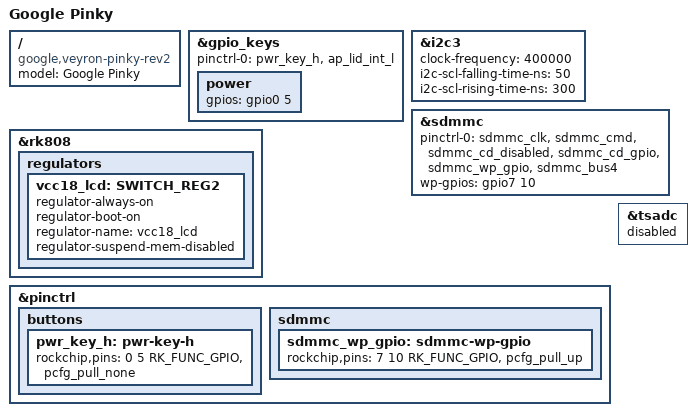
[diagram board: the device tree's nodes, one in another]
/*
 * Google Veyron Pinky Rev 2 board device tree source
 *
 * Copyright 2014 Google, Inc
 *
 * This program is free software; you can redistribute it and/or modify
 * it under the terms of the GNU General Public License version 2 as
 * published by the Free Software Foundation.
 */

/dts-v1/;
#include "rk3288-veyron-chromebook.dtsi"
#include "cros-ec-sbs.dtsi"

/ {
	model = "Google Pinky";
	compatible = "google,veyron-pinky-rev2", "google,veyron-pinky",
		     "google,veyron", "rockchip,rk3288";
};

&gpio_keys {
	pinctrl-0 = <&pwr_key_h &ap_lid_int_l>;

	power {
		gpios = <&gpio0 5 GPIO_ACTIVE_HIGH>;
	};
};

/* Touchpad connector */
&i2c3 {
	status = "okay";

	clock-frequency = <400000>;
	i2c-scl-falling-time-ns = <50>;
	i2c-scl-rising-time-ns = <300>;
};

&sdmmc {
	pinctrl-names = "default";
	pinctrl-0 = <&sdmmc_clk &sdmmc_cmd &sdmmc_cd_disabled &sdmmc_cd_gpio
		     &sdmmc_wp_gpio &sdmmc_bus4>;
	wp-gpios = <&gpio7 10 GPIO_ACTIVE_HIGH>;
};

&rk808 {
	regulators {
		vcc18_lcd: SWITCH_REG2 {
			regulator-always-on;
			regulator-boot-on;
			regulator-name = "vcc18_lcd";
			regulator-suspend-mem-disabled;
		};
	};
};

&pinctrl {
	buttons {
		pwr_key_h: pwr-key-h {
			rockchip,pins = <0 5 RK_FUNC_GPIO &pcfg_pull_none>;
		};
	};

	sdmmc {
		sdmmc_wp_gpio: sdmmc-wp-gpio {
			rockchip,pins = <7 10 RK_FUNC_GPIO &pcfg_pull_up>;
		};
	};
};

&tsadc {
	/* Some connection is flaky making the tsadc hang the system */
	status = "disabled";
};
